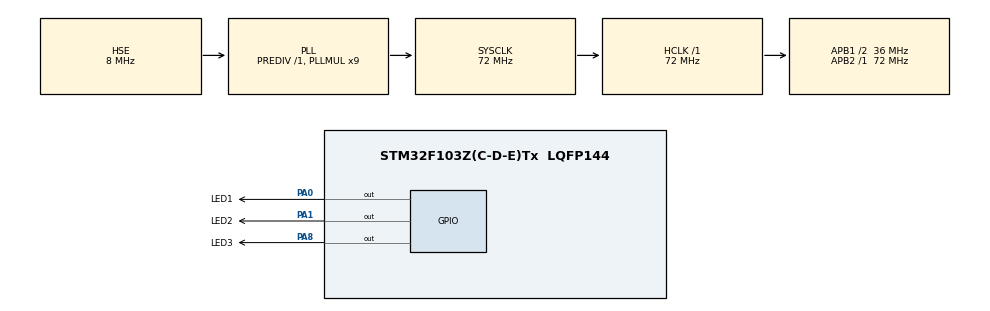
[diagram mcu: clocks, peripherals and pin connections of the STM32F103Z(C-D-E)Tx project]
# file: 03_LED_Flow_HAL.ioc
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Mcu.Family=STM32F1
Mcu.Name=STM32F103Z(C-D-E)Tx
Mcu.Package=LQFP144
NVIC.PriorityGroup=NVIC_PRIORITYGROUP_4
OSC_IN.Mode=HSE-External-Oscillator
OSC_IN.Signal=RCC_OSC_IN
OSC_OUT.Mode=HSE-External-Oscillator
OSC_OUT.Signal=RCC_OSC_OUT
PA0-WKUP.GPIO_Label=LED1
PA0-WKUP.GPIO_ModeDefaultOutputPP=GPIO_MODE_OUTPUT_PP
PA0-WKUP.GPIO_Speed=GPIO_SPEED_FREQ_HIGH
PA0-WKUP.PinState=GPIO_PIN_SET
PA0-WKUP.Signal=GPIO_Output
PA1.GPIO_Label=LED2
PA1.GPIO_PuPd=GPIO_NOPULL
PA1.GPIO_Speed=GPIO_SPEED_FREQ_HIGH
PA1.PinState=GPIO_PIN_SET
PA1.Signal=GPIO_Output
PA13.Mode=Serial_Wire
PA13.Signal=SYS_JTMS-SWDIO
PA14.Mode=Serial_Wire
PA14.Signal=SYS_JTCK-SWCLK
PA8.GPIO_Label=LED3
PA8.GPIO_Speed=GPIO_SPEED_FREQ_HIGH
PA8.PinState=GPIO_PIN_SET
PA8.Signal=GPIO_Output
PC14-OSC32_IN.Mode=LSE-External-Oscillator
PC14-OSC32_IN.Signal=RCC_OSC32_IN
PC15-OSC32_OUT.Mode=LSE-External-Oscillator
PC15-OSC32_OUT.Signal=RCC_OSC32_OUT
ProjectManager.HeapSize=0x200
ProjectManager.StackSize=0x400
ProjectManager.TargetToolchain=MDK-ARM V5.32
RCC.AHBFreq_Value=72000000
RCC.APB1CLKDivider=RCC_HCLK_DIV2
RCC.APB1Freq_Value=36000000
RCC.APB1TimFreq_Value=72000000
RCC.APB2Freq_Value=72000000
RCC.APB2TimFreq_Value=72000000
RCC.HCLKFreq_Value=72000000
RCC.PLLMUL=RCC_PLL_MUL9
RCC.PLLSourceVirtual=RCC_PLLSOURCE_HSE
RCC.SYSCLKFreq_VALUE=72000000
RCC.SYSCLKSource=RCC_SYSCLKSOURCE_PLLCLK
RCC.USBFreq_Value=72000000
board=custom

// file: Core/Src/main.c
/* USER CODE BEGIN Header */
/**
 ******************************************************************************
 * @file           : main.c
 * @brief          : Main program body
 ******************************************************************************
 * @attention
 *
 * Copyright (c) 2025 STMicroelectronics.
 * All rights reserved.
 *
 * This software is licensed under terms that can be found in the LICENSE file
 * in the root directory of this software component.
 * If no LICENSE file comes with this software, it is provided AS-IS.
 *
 ******************************************************************************
 */
/**
 * 架构图:
 * 被动单元:在整个电路中，这部分电路不会主动做事情
 * 三个被动单元：
 *  1. 内部SRAM:存储程序执行时用到的变量
 *  2. 内部闪存存储器FLASH:存储程序执行时用到的变量
 *     a. 存储下载的程序
 *     b. 程序执行时用到的常量
 *  3.AHB到APB的桥(AHB到APBx) AHB就相当于扩展坞,例如自己用到的一个usb分出多个usb接口
 *    桥1:连接APB2 72MHz 高速外设
 *    桥2:连接APB1 36MHz 低速外设
 */

/**
 * 四个驱动(主动)单元
 * 计算机总一般有三大总线:地址总线 数据总线 控制总线
 * 1.DCode:相当于数据总线
 * 2.system:地址总线和控制总线的合二为一
 * 3.DMA1
 * 4.DMA2
 * 这四个驱动单元都和总线矩阵相连
 *   总线矩阵就相当于转接员的角色。相当于网络中的路由器或交换机的功能
 *
 * 其它单元
 * 1.ICode:连接Flash,实现指令的读取
 * 2.FSMC:用来扩展外部的SRAM,Flash,连接LCD屏幕等
 *
 */

/**
 * 时钟树:时钟树是一套硬件电路，控制时钟的生成和时钟的供给。
 *  问:为什么芯片内部有时钟源却不用?
 *   首先晶振是没办法做到小型化的,芯片内部时钟是不可能用晶振做的,是用RC震荡电路实现的,
 *   但是RC震荡电路对温度很敏感,容易得到一个不稳定的时钟信号,例如在串口通讯或者时序要求
 *   比较严格的地方就非常不合适。但是晶振对温度就不是很敏感。如果从节约成本上又不影响性能
 *   的产品就可以用内部时钟。例如就简单的做个闹钟。
 *
 *   锁相环是倍频器,是倍频器的一种实现方式,倍频器有很多种实现方式,锁相环是其中一种实现方式。
 *   倍频器的作用就是把一个频率较低的时钟信号转换成一个频率较高的时钟信号。
 */

/**
 * 如果构建HAL项目:
 * 1.sys系统工作模式:烧录程序的方式
 *   no debug中选择serial wire串行线
 *   如果没有选择是no bug,也可以烧录，但是芯片是没办法再烧录第二次
 *   如果想再重新烧录,必须修改启动模式为bootLoader模式
 * 2.RCC设置:HSE和LSE都选择Crystal/Ceramic Resonator
 * 3.Clock Configuration:因为再RCC设置了,所以HSE和LSE两个值都是蓝色并可用
 * 4.GPOI引脚配置
 *   GPIO Output Level:表示一上电时的电平
 *                      High:高电平--->没电
 *                      Low:低电平--->有电
 *
 * 不要再MDK-ARM文件里建新文件
 */

#include "main.h"
#include "gpio.h"

void SystemClock_Config(void);

int main(void)
{

  /* Reset of all peripherals, Initializes the Flash interface and the Systick.
     复位所有外设，初始化闪存接口与系统滴答定时器。
   */
  HAL_Init();

  /* Configure the system clock */
  SystemClock_Config();

  /* Initialize all configured peripherals
     前缀MX_ 表示的事经过CUBEMX配置过的外设初始化函数
     The prefix MX_ refers to peripheral initialization functions configured via CUBEMX.
   */
  MX_GPIO_Init();

  /* USER CODE BEGIN 2 */
    // HAL_GPIO_WritePin(GPIOA,GPIO_PIN_8,GPIO_PIN_RESET);
    // HAL_GPIO_WritePin(LED1_GPIO_Port,LED1_Pin,GPIO_PIN_RESET);
  /* USER CODE END 2 */

  /* Infinite loop */
  /* USER CODE BEGIN WHILE */
  uint32_t leds[] = {LED1_Pin, LED2_Pin, LED3_Pin};
  while (1)
  {
    // 流水灯效果 start------------------
    /**for(uint8_t i=0;i<sizeof(leds)/sizeof(uint32_t);i++){
      HAL_GPIO_WritePin(GPIOA,leds[i],GPIO_PIN_RESET);
      HAL_Delay(500);
    }

    for(uint8_t i=0;i<sizeof(leds)/sizeof(uint32_t);i++){
      HAL_GPIO_WritePin(GPIOA,leds[2-i],GPIO_PIN_SET);
      HAL_Delay(500);
    }
    */
    // 流水灯效果 end------------------
    HAL_GPIO_TogglePin(GPIOA, leds[0]);
    HAL_Delay(500);

    /* USER CODE END WHILE */

  }
}

void SystemClock_Config(void)
{
  RCC_OscInitTypeDef RCC_OscInitStruct = {0};
  RCC_ClkInitTypeDef RCC_ClkInitStruct = {0};

  /** Initializes the RCC Oscillators according to the specified parameters
   * in the RCC_OscInitTypeDef structure.
   */
  RCC_OscInitStruct.OscillatorType = RCC_OSCILLATORTYPE_HSE;
  RCC_OscInitStruct.HSEState = RCC_HSE_ON;
  RCC_OscInitStruct.HSEPredivValue = RCC_HSE_PREDIV_DIV1;
  RCC_OscInitStruct.HSIState = RCC_HSI_ON;
  RCC_OscInitStruct.PLL.PLLState = RCC_PLL_ON;
  RCC_OscInitStruct.PLL.PLLSource = RCC_PLLSOURCE_HSE;
  RCC_OscInitStruct.PLL.PLLMUL = RCC_PLL_MUL9;
  if (HAL_RCC_OscConfig(&RCC_OscInitStruct) != HAL_OK)
  {
    Error_Handler();
  }

  /** Initializes the CPU, AHB and APB buses clocks
   */
  RCC_ClkInitStruct.ClockType = RCC_CLOCKTYPE_HCLK | RCC_CLOCKTYPE_SYSCLK | RCC_CLOCKTYPE_PCLK1 | RCC_CLOCKTYPE_PCLK2;
  RCC_ClkInitStruct.SYSCLKSource = RCC_SYSCLKSOURCE_PLLCLK;
  RCC_ClkInitStruct.AHBCLKDivider = RCC_SYSCLK_DIV1;
  RCC_ClkInitStruct.APB1CLKDivider = RCC_HCLK_DIV2;
  RCC_ClkInitStruct.APB2CLKDivider = RCC_HCLK_DIV1;

  if (HAL_RCC_ClockConfig(&RCC_ClkInitStruct, FLASH_LATENCY_2) != HAL_OK)
  {
    Error_Handler();
  }
}

void Error_Handler(void)
{
  __disable_irq();
  while (1)
  {
  }
}
